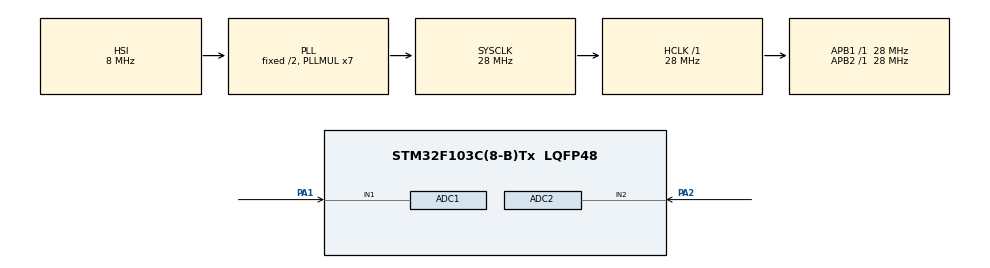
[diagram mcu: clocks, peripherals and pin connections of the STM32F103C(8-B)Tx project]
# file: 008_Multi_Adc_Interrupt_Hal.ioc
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ADC1.Channel-2\#ChannelRegularConversion=ADC_CHANNEL_1
ADC1.Channel-3\#ChannelRegularConversion=ADC_CHANNEL_VREFINT
ADC1.Channel-4\#ChannelRegularConversion=ADC_CHANNEL_TEMPSENSOR
ADC1.ContinuousConvMode=ENABLE
ADC1.NbrOfConversion=3
ADC1.NbrOfConversionFlag=1
ADC1.Rank-2\#ChannelRegularConversion=1
ADC1.Rank-3\#ChannelRegularConversion=2
ADC1.Rank-4\#ChannelRegularConversion=3
ADC1.SamplingTime-2\#ChannelRegularConversion=ADC_SAMPLETIME_28CYCLES_5
ADC1.SamplingTime-3\#ChannelRegularConversion=ADC_SAMPLETIME_41CYCLES_5
ADC1.SamplingTime-4\#ChannelRegularConversion=ADC_SAMPLETIME_71CYCLES_5
ADC1.master=1
ADC2.Channel-0\#ChannelRegularConversion=ADC_CHANNEL_2
ADC2.ContinuousConvMode=ENABLE
ADC2.NbrOfConversionFlag=1
ADC2.Rank-0\#ChannelRegularConversion=1
ADC2.SamplingTime-0\#ChannelRegularConversion=ADC_SAMPLETIME_55CYCLES_5
Mcu.Family=STM32F1
Mcu.Name=STM32F103C(8-B)Tx
Mcu.Package=LQFP48
NVIC.ADC1_2_IRQn=true\:0\:0\:false\:false\:true\:true\:true\:true
NVIC.PriorityGroup=NVIC_PRIORITYGROUP_4
PA1.Signal=ADCx_IN1
PA13.Mode=Serial_Wire
PA13.Signal=SYS_JTMS-SWDIO
PA14.Mode=Serial_Wire
PA14.Signal=SYS_JTCK-SWCLK
PA2.Signal=ADCx_IN2
PD0-OSC_IN.Mode=HSE-External-Oscillator
PD0-OSC_IN.Signal=RCC_OSC_IN
PD1-OSC_OUT.Mode=HSE-External-Oscillator
PD1-OSC_OUT.Signal=RCC_OSC_OUT
ProjectManager.HeapSize=0x200
ProjectManager.StackSize=0x400
ProjectManager.TargetToolchain=STM32CubeIDE
RCC.AHBFreq_Value=28000000
RCC.APB1Freq_Value=28000000
RCC.APB1TimFreq_Value=28000000
RCC.APB2Freq_Value=28000000
RCC.APB2TimFreq_Value=28000000
RCC.HCLKFreq_Value=28000000
RCC.PLLMUL=RCC_PLL_MUL7
RCC.SYSCLKFreq_VALUE=28000000
RCC.SYSCLKSource=RCC_SYSCLKSOURCE_PLLCLK
RCC.USBFreq_Value=28000000
SH.ADCx_IN1.0=ADC1_IN1,IN1
SH.ADCx_IN2.0=ADC2_IN2,IN2
VP_ADC1_TempSens_Input.Mode=IN-TempSens
VP_ADC1_Vref_Input.Mode=IN-Vrefint
board=custom

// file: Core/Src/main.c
/* USER CODE BEGIN Header */
/**
  ******************************************************************************
  * @file           : main.c
  * @brief          : Main program body
  ******************************************************************************
  * @attention
  *
  * Copyright (c) 2024 STMicroelectronics.
  * All rights reserved.
  *
  * This software is licensed under terms that can be found in the LICENSE file
  * in the root directory of this software component.
  * If no LICENSE file comes with this software, it is provided AS-IS.
  *
  ******************************************************************************
  */
/* USER CODE END Header */
#include "main.h"

/* USER CODE BEGIN Includes */
#define VREFIN_CAL (uint16_t) 1.20
#define V25 (float) 1.43
#define AVG_SLOPE (float) 0.0043

uint16_t adc1_value[3], adc2_value;
float Vadc1 = 0, Vadc2 = 0, Vsens = 0, Vdd =  0, temperature = 0;
int count = 0;

/* USER CODE END Includes */

ADC_HandleTypeDef hadc1;
ADC_HandleTypeDef hadc2;

void SystemClock_Config(void);
static void MX_GPIO_Init(void);
static void MX_ADC1_Init(void);
static void MX_ADC2_Init(void);

/* USER CODE BEGIN 0 */
void HAL_ADC_ConvCpltCallback(ADC_HandleTypeDef* hadc)
{
	if(__HAL_ADC_GET_FLAG(&hadc1,ADC_FLAG_EOC) != RESET){

		//HAL_Delay(500);
		adc1_value[3] = HAL_ADC_GetValue(&hadc1);
		count++;

		if(count == 2)
			count =0;

		Vdd = (float) 3.3 * VREFIN_CAL / adc1_value[1];
		Vadc1 = Vdd * adc1_value[0] / 4095;

		Vsens = Vdd * adc1_value[2] / 4095;
		temperature = ((Vsens - V25) / AVG_SLOPE) + 25;

	}
	if(__HAL_ADC_GET_FLAG(&hadc2, ADC_FLAG_EOC) != RESET){

		adc2_value = HAL_ADC_GetValue(&hadc2);

		Vadc2 = Vdd * adc2_value / 4095;

	}

}

/* USER CODE END 0 */

int main(void)
{

  /* MCU Configuration--------------------------------------------------------*/

  /* Reset of all peripherals, Initializes the Flash interface and the Systick. */
  HAL_Init();

  /* Configure the system clock */
  SystemClock_Config();

  /* Initialize all configured peripherals */
  MX_GPIO_Init();
  MX_ADC1_Init();
  MX_ADC2_Init();
  /* USER CODE BEGIN 2 */
  HAL_ADC_Start_IT(&hadc1);
  HAL_ADC_Start_IT(&hadc2);

//  ADC1->CR1

  /* USER CODE END 2 */

  /* Infinite loop */
  while (1)
  {

  }
}

void SystemClock_Config(void)
{
  RCC_OscInitTypeDef RCC_OscInitStruct = {0};
  RCC_ClkInitTypeDef RCC_ClkInitStruct = {0};
  RCC_PeriphCLKInitTypeDef PeriphClkInit = {0};

  /** Initializes the RCC Oscillators according to the specified parameters
  * in the RCC_OscInitTypeDef structure.
  */
  RCC_OscInitStruct.OscillatorType = RCC_OSCILLATORTYPE_HSI;
  RCC_OscInitStruct.HSIState = RCC_HSI_ON;
  RCC_OscInitStruct.HSICalibrationValue = RCC_HSICALIBRATION_DEFAULT;
  RCC_OscInitStruct.PLL.PLLState = RCC_PLL_ON;
  RCC_OscInitStruct.PLL.PLLSource = RCC_PLLSOURCE_HSI_DIV2;
  RCC_OscInitStruct.PLL.PLLMUL = RCC_PLL_MUL7;
  if (HAL_RCC_OscConfig(&RCC_OscInitStruct) != HAL_OK)
  {
    Error_Handler();
  }

  /** Initializes the CPU, AHB and APB buses clocks
  */
  RCC_ClkInitStruct.ClockType = RCC_CLOCKTYPE_HCLK|RCC_CLOCKTYPE_SYSCLK
                              |RCC_CLOCKTYPE_PCLK1|RCC_CLOCKTYPE_PCLK2;
  RCC_ClkInitStruct.SYSCLKSource = RCC_SYSCLKSOURCE_PLLCLK;
  RCC_ClkInitStruct.AHBCLKDivider = RCC_SYSCLK_DIV1;
  RCC_ClkInitStruct.APB1CLKDivider = RCC_HCLK_DIV1;
  RCC_ClkInitStruct.APB2CLKDivider = RCC_HCLK_DIV1;

  if (HAL_RCC_ClockConfig(&RCC_ClkInitStruct, FLASH_LATENCY_1) != HAL_OK)
  {
    Error_Handler();
  }
  PeriphClkInit.PeriphClockSelection = RCC_PERIPHCLK_ADC;
  PeriphClkInit.AdcClockSelection = RCC_ADCPCLK2_DIV2;
  if (HAL_RCCEx_PeriphCLKConfig(&PeriphClkInit) != HAL_OK)
  {
    Error_Handler();
  }
}

static void MX_ADC1_Init(void)
{

  ADC_ChannelConfTypeDef sConfig = {0};

  /** Common config
  */
  hadc1.Instance = ADC1;
  hadc1.Init.ScanConvMode = ADC_SCAN_ENABLE;
  hadc1.Init.ContinuousConvMode = ENABLE;
  hadc1.Init.DiscontinuousConvMode = DISABLE;
  hadc1.Init.ExternalTrigConv = ADC_SOFTWARE_START;
  hadc1.Init.DataAlign = ADC_DATAALIGN_RIGHT;
  hadc1.Init.NbrOfConversion = 3;
  if (HAL_ADC_Init(&hadc1) != HAL_OK)
  {
    Error_Handler();
  }

  /** Configure Regular Channel
  */
  sConfig.Channel = ADC_CHANNEL_1;
  sConfig.Rank = ADC_REGULAR_RANK_1;
  sConfig.SamplingTime = ADC_SAMPLETIME_28CYCLES_5;
  if (HAL_ADC_ConfigChannel(&hadc1, &sConfig) != HAL_OK)
  {
    Error_Handler();
  }

  /** Configure Regular Channel
  */
  sConfig.Channel = ADC_CHANNEL_VREFINT;
  sConfig.Rank = ADC_REGULAR_RANK_2;
  sConfig.SamplingTime = ADC_SAMPLETIME_41CYCLES_5;
  if (HAL_ADC_ConfigChannel(&hadc1, &sConfig) != HAL_OK)
  {
    Error_Handler();
  }

  /** Configure Regular Channel
  */
  sConfig.Channel = ADC_CHANNEL_TEMPSENSOR;
  sConfig.Rank = ADC_REGULAR_RANK_3;
  sConfig.SamplingTime = ADC_SAMPLETIME_71CYCLES_5;
  if (HAL_ADC_ConfigChannel(&hadc1, &sConfig) != HAL_OK)
  {
    Error_Handler();
  }

}

static void MX_ADC2_Init(void)
{

  ADC_ChannelConfTypeDef sConfig = {0};

  /** Common config
  */
  hadc2.Instance = ADC2;
  hadc2.Init.ScanConvMode = ADC_SCAN_DISABLE;
  hadc2.Init.ContinuousConvMode = ENABLE;
  hadc2.Init.DiscontinuousConvMode = DISABLE;
  hadc2.Init.ExternalTrigConv = ADC_SOFTWARE_START;
  hadc2.Init.DataAlign = ADC_DATAALIGN_RIGHT;
  hadc2.Init.NbrOfConversion = 1;
  if (HAL_ADC_Init(&hadc2) != HAL_OK)
  {
    Error_Handler();
  }

  /** Configure Regular Channel
  */
  sConfig.Channel = ADC_CHANNEL_2;
  sConfig.Rank = ADC_REGULAR_RANK_1;
  sConfig.SamplingTime = ADC_SAMPLETIME_55CYCLES_5;
  if (HAL_ADC_ConfigChannel(&hadc2, &sConfig) != HAL_OK)
  {
    Error_Handler();
  }

}

static void MX_GPIO_Init(void)
{

  /* GPIO Ports Clock Enable */
  __HAL_RCC_GPIOD_CLK_ENABLE();
  __HAL_RCC_GPIOA_CLK_ENABLE();

}

void Error_Handler(void)
{
  __disable_irq();
  while (1)
  {
  }
}
